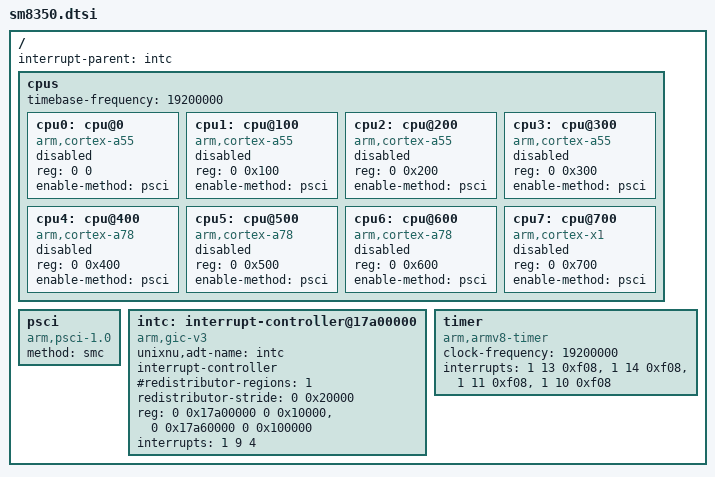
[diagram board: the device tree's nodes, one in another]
// SPDX-License-Identifier: BSD-3-Clause
// Minimal resources derived from Linux v6.12 qcom/sm8350.dtsi.
/ {
    #address-cells = <2>;
    #size-cells = <2>;
    interrupt-parent = <&intc>;

    cpus {
        #address-cells = <2>;
        #size-cells = <0>;
        // The ADT generator reads the architectural timer frequency here.
        timebase-frequency = <19200000>;
        cpu0: cpu@0 { device_type = "cpu"; compatible = "arm,cortex-a55"; reg = <0 0>; enable-method = "psci"; status = "disabled"; };
        cpu1: cpu@100 { device_type = "cpu"; compatible = "arm,cortex-a55"; reg = <0 0x100>; enable-method = "psci"; status = "disabled"; };
        cpu2: cpu@200 { device_type = "cpu"; compatible = "arm,cortex-a55"; reg = <0 0x200>; enable-method = "psci"; status = "disabled"; };
        cpu3: cpu@300 { device_type = "cpu"; compatible = "arm,cortex-a55"; reg = <0 0x300>; enable-method = "psci"; status = "disabled"; };
        cpu4: cpu@400 { device_type = "cpu"; compatible = "arm,cortex-a78"; reg = <0 0x400>; enable-method = "psci"; status = "disabled"; };
        cpu5: cpu@500 { device_type = "cpu"; compatible = "arm,cortex-a78"; reg = <0 0x500>; enable-method = "psci"; status = "disabled"; };
        cpu6: cpu@600 { device_type = "cpu"; compatible = "arm,cortex-a78"; reg = <0 0x600>; enable-method = "psci"; status = "disabled"; };
        cpu7: cpu@700 { device_type = "cpu"; compatible = "arm,cortex-x1"; reg = <0 0x700>; enable-method = "psci"; status = "disabled"; };
    };

    psci { compatible = "arm,psci-1.0"; method = "smc"; };

    intc: interrupt-controller@17a00000 {
        compatible = "arm,gic-v3";
        // ArmCpu::mapGic consumes /arm-io/intc in the generated ADT.
        unixnu,adt-name = "intc";
        interrupt-controller;
        #interrupt-cells = <3>;
        #redistributor-regions = <1>;
        redistributor-stride = <0 0x20000>;
        reg = <0 0x17a00000 0 0x10000>, <0 0x17a60000 0 0x100000>;
        interrupts = <1 9 4>;
    };

    timer {
        compatible = "arm,armv8-timer";
        clock-frequency = <19200000>;
        interrupts = <1 13 0xf08>, <1 14 0xf08>, <1 11 0xf08>, <1 10 0xf08>;
    };
};
